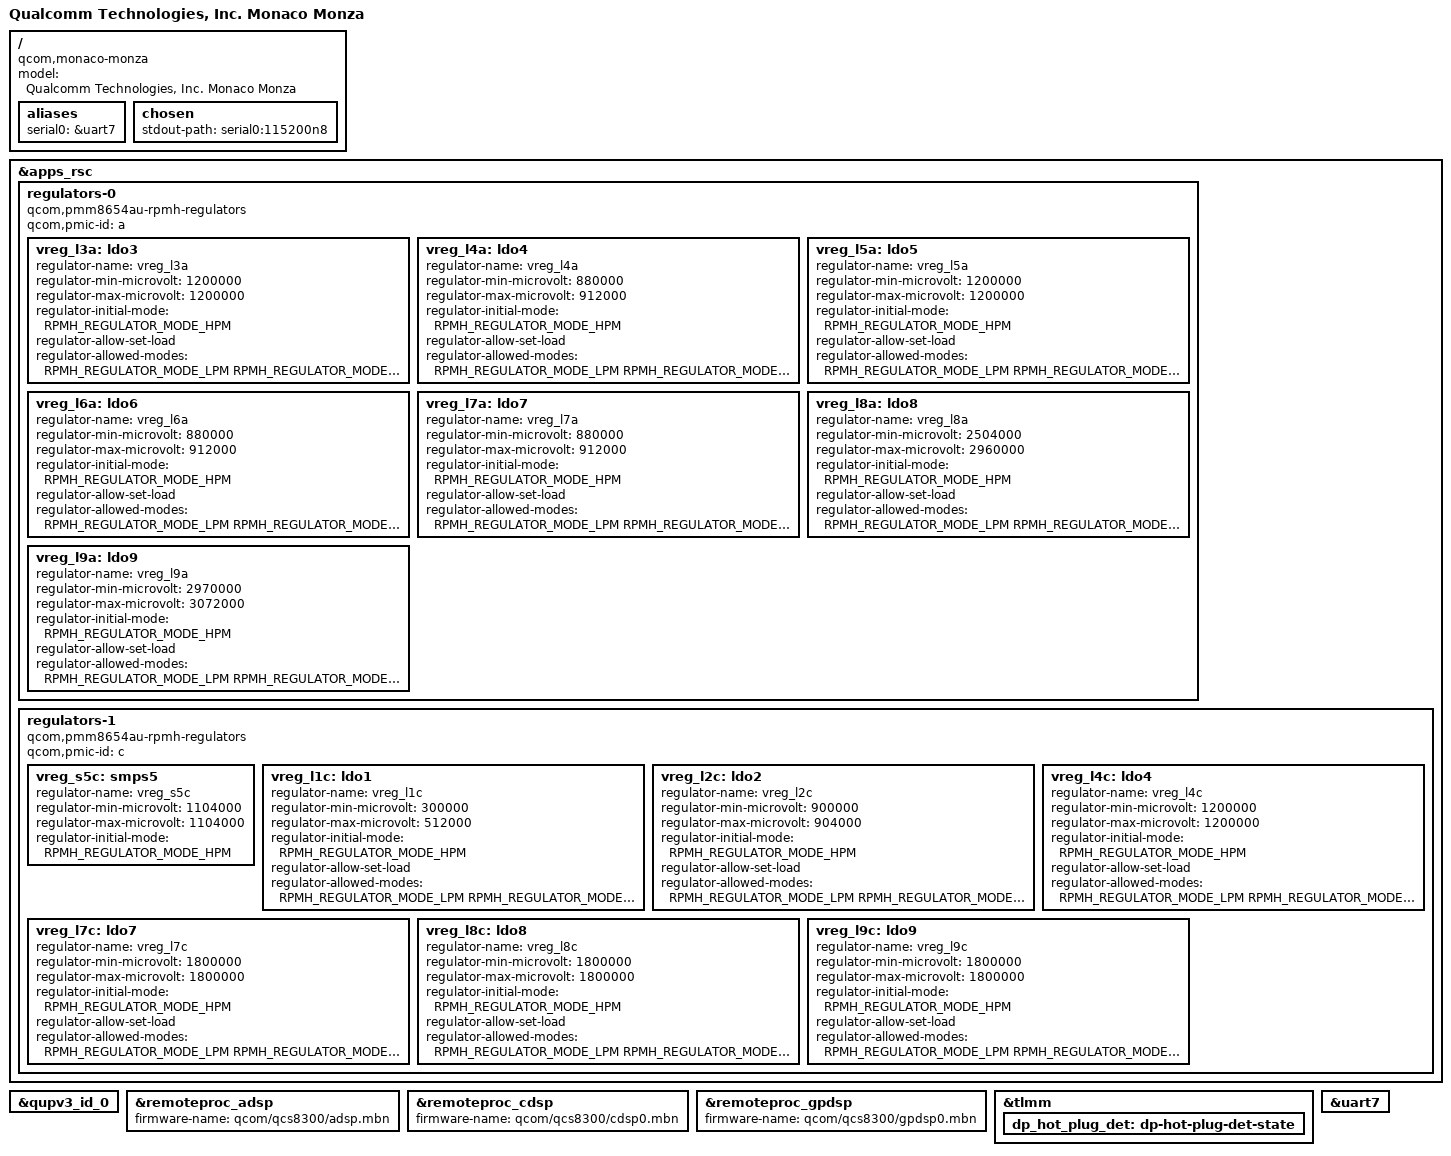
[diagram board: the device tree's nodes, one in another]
// SPDX-License-Identifier: BSD-3-Clause
/*
 * Copyright (c) Qualcomm Technologies, Inc. and/or its subsidiaries.
 */

/dts-v1/;

#include <dt-bindings/regulator/qcom,rpmh-regulator.h>
#include <dt-bindings/spmi/spmi.h>
#include "qcs8300.dtsi"
#include "qcs8300-thermal.dtsi"
#include "qcs8300-pmics.dtsi"

/ {
	model = "Qualcomm Technologies, Inc. Monaco Monza";
	compatible = "qcom,monaco-monza", "qcom,qcs8300";

	aliases {
		serial0 = &uart7;
	};

	chosen {
		stdout-path = "serial0:115200n8";
	};
};

&apps_rsc {
	regulators-0 {
		compatible = "qcom,pmm8654au-rpmh-regulators";
		qcom,pmic-id = "a";

		vreg_l3a: ldo3 {
			regulator-name = "vreg_l3a";
			regulator-min-microvolt = <1200000>;
			regulator-max-microvolt = <1200000>;
			regulator-initial-mode = <RPMH_REGULATOR_MODE_HPM>;
			regulator-allow-set-load;
			regulator-allowed-modes = <RPMH_REGULATOR_MODE_LPM
						   RPMH_REGULATOR_MODE_HPM>;
		};

		vreg_l4a: ldo4 {
			regulator-name = "vreg_l4a";
			regulator-min-microvolt = <880000>;
			regulator-max-microvolt = <912000>;
			regulator-initial-mode = <RPMH_REGULATOR_MODE_HPM>;
			regulator-allow-set-load;
			regulator-allowed-modes = <RPMH_REGULATOR_MODE_LPM
						   RPMH_REGULATOR_MODE_HPM>;
		};

		vreg_l5a: ldo5 {
			regulator-name = "vreg_l5a";
			regulator-min-microvolt = <1200000>;
			regulator-max-microvolt = <1200000>;
			regulator-initial-mode = <RPMH_REGULATOR_MODE_HPM>;
			regulator-allow-set-load;
			regulator-allowed-modes = <RPMH_REGULATOR_MODE_LPM
						   RPMH_REGULATOR_MODE_HPM>;
		};

		vreg_l6a: ldo6 {
			regulator-name = "vreg_l6a";
			regulator-min-microvolt = <880000>;
			regulator-max-microvolt = <912000>;
			regulator-initial-mode = <RPMH_REGULATOR_MODE_HPM>;
			regulator-allow-set-load;
			regulator-allowed-modes = <RPMH_REGULATOR_MODE_LPM
						   RPMH_REGULATOR_MODE_HPM>;
		};

		vreg_l7a: ldo7 {
			regulator-name = "vreg_l7a";
			regulator-min-microvolt = <880000>;
			regulator-max-microvolt = <912000>;
			regulator-initial-mode = <RPMH_REGULATOR_MODE_HPM>;
			regulator-allow-set-load;
			regulator-allowed-modes = <RPMH_REGULATOR_MODE_LPM
						   RPMH_REGULATOR_MODE_HPM>;
		};

		vreg_l8a: ldo8 {
			regulator-name = "vreg_l8a";
			regulator-min-microvolt = <2504000>;
			regulator-max-microvolt = <2960000>;
			regulator-initial-mode = <RPMH_REGULATOR_MODE_HPM>;
			regulator-allow-set-load;
			regulator-allowed-modes = <RPMH_REGULATOR_MODE_LPM
						   RPMH_REGULATOR_MODE_HPM>;
		};

		vreg_l9a: ldo9 {
			regulator-name = "vreg_l9a";
			regulator-min-microvolt = <2970000>;
			regulator-max-microvolt = <3072000>;
			regulator-initial-mode = <RPMH_REGULATOR_MODE_HPM>;
			regulator-allow-set-load;
			regulator-allowed-modes = <RPMH_REGULATOR_MODE_LPM
						   RPMH_REGULATOR_MODE_HPM>;
		};
	};

	regulators-1 {
		compatible = "qcom,pmm8654au-rpmh-regulators";
		qcom,pmic-id = "c";

		vreg_s5c: smps5 {
			regulator-name = "vreg_s5c";
			regulator-min-microvolt = <1104000>;
			regulator-max-microvolt = <1104000>;
			regulator-initial-mode = <RPMH_REGULATOR_MODE_HPM>;
		};

		vreg_l1c: ldo1 {
			regulator-name = "vreg_l1c";
			regulator-min-microvolt = <300000>;
			regulator-max-microvolt = <512000>;
			regulator-initial-mode = <RPMH_REGULATOR_MODE_HPM>;
			regulator-allow-set-load;
			regulator-allowed-modes = <RPMH_REGULATOR_MODE_LPM
						   RPMH_REGULATOR_MODE_HPM>;
		};

		vreg_l2c: ldo2 {
			regulator-name = "vreg_l2c";
			regulator-min-microvolt = <900000>;
			regulator-max-microvolt = <904000>;
			regulator-initial-mode = <RPMH_REGULATOR_MODE_HPM>;
			regulator-allow-set-load;
			regulator-allowed-modes = <RPMH_REGULATOR_MODE_LPM
						   RPMH_REGULATOR_MODE_HPM>;
		};

		vreg_l4c: ldo4 {
			regulator-name = "vreg_l4c";
			regulator-min-microvolt = <1200000>;
			regulator-max-microvolt = <1200000>;
			regulator-initial-mode = <RPMH_REGULATOR_MODE_HPM>;
			regulator-allow-set-load;
			regulator-allowed-modes = <RPMH_REGULATOR_MODE_LPM
						   RPMH_REGULATOR_MODE_HPM>;
		};

		vreg_l7c: ldo7 {
			regulator-name = "vreg_l7c";
			regulator-min-microvolt = <1800000>;
			regulator-max-microvolt = <1800000>;
			regulator-initial-mode = <RPMH_REGULATOR_MODE_HPM>;
			regulator-allow-set-load;
			regulator-allowed-modes = <RPMH_REGULATOR_MODE_LPM
						   RPMH_REGULATOR_MODE_HPM>;
		};

		vreg_l8c: ldo8 {
			regulator-name = "vreg_l8c";
			regulator-min-microvolt = <1800000>;
			regulator-max-microvolt = <1800000>;
			regulator-initial-mode = <RPMH_REGULATOR_MODE_HPM>;
			regulator-allow-set-load;
			regulator-allowed-modes = <RPMH_REGULATOR_MODE_LPM
						   RPMH_REGULATOR_MODE_HPM>;
		};

		vreg_l9c: ldo9 {
			regulator-name = "vreg_l9c";
			regulator-min-microvolt = <1800000>;
			regulator-max-microvolt = <1800000>;
			regulator-initial-mode = <RPMH_REGULATOR_MODE_HPM>;
			regulator-allow-set-load;
			regulator-allowed-modes = <RPMH_REGULATOR_MODE_LPM
						   RPMH_REGULATOR_MODE_HPM>;
		};
	};
};

&qupv3_id_0 {
	status = "okay";
};

&remoteproc_adsp {
	firmware-name = "qcom/qcs8300/adsp.mbn";

	status = "okay";
};

&remoteproc_cdsp {
	firmware-name = "qcom/qcs8300/cdsp0.mbn";

	status = "okay";
};

&remoteproc_gpdsp {
	firmware-name = "qcom/qcs8300/gpdsp0.mbn";

	status = "okay";
};

&tlmm {

	dp_hot_plug_det: dp-hot-plug-det-state {
		/*
		 * TODO: Replace this placeholder with the final DisplayPort (DP) controller
		 * node definition. This dummy node currently satisfies compilation dependencies
		 * for the DP driver added in QCS8300 SoC, but it will be updated once DP support
		 * for monaco-monza is fully enabled.
		 */
	};
};

&uart7 {
	status = "okay";
};
